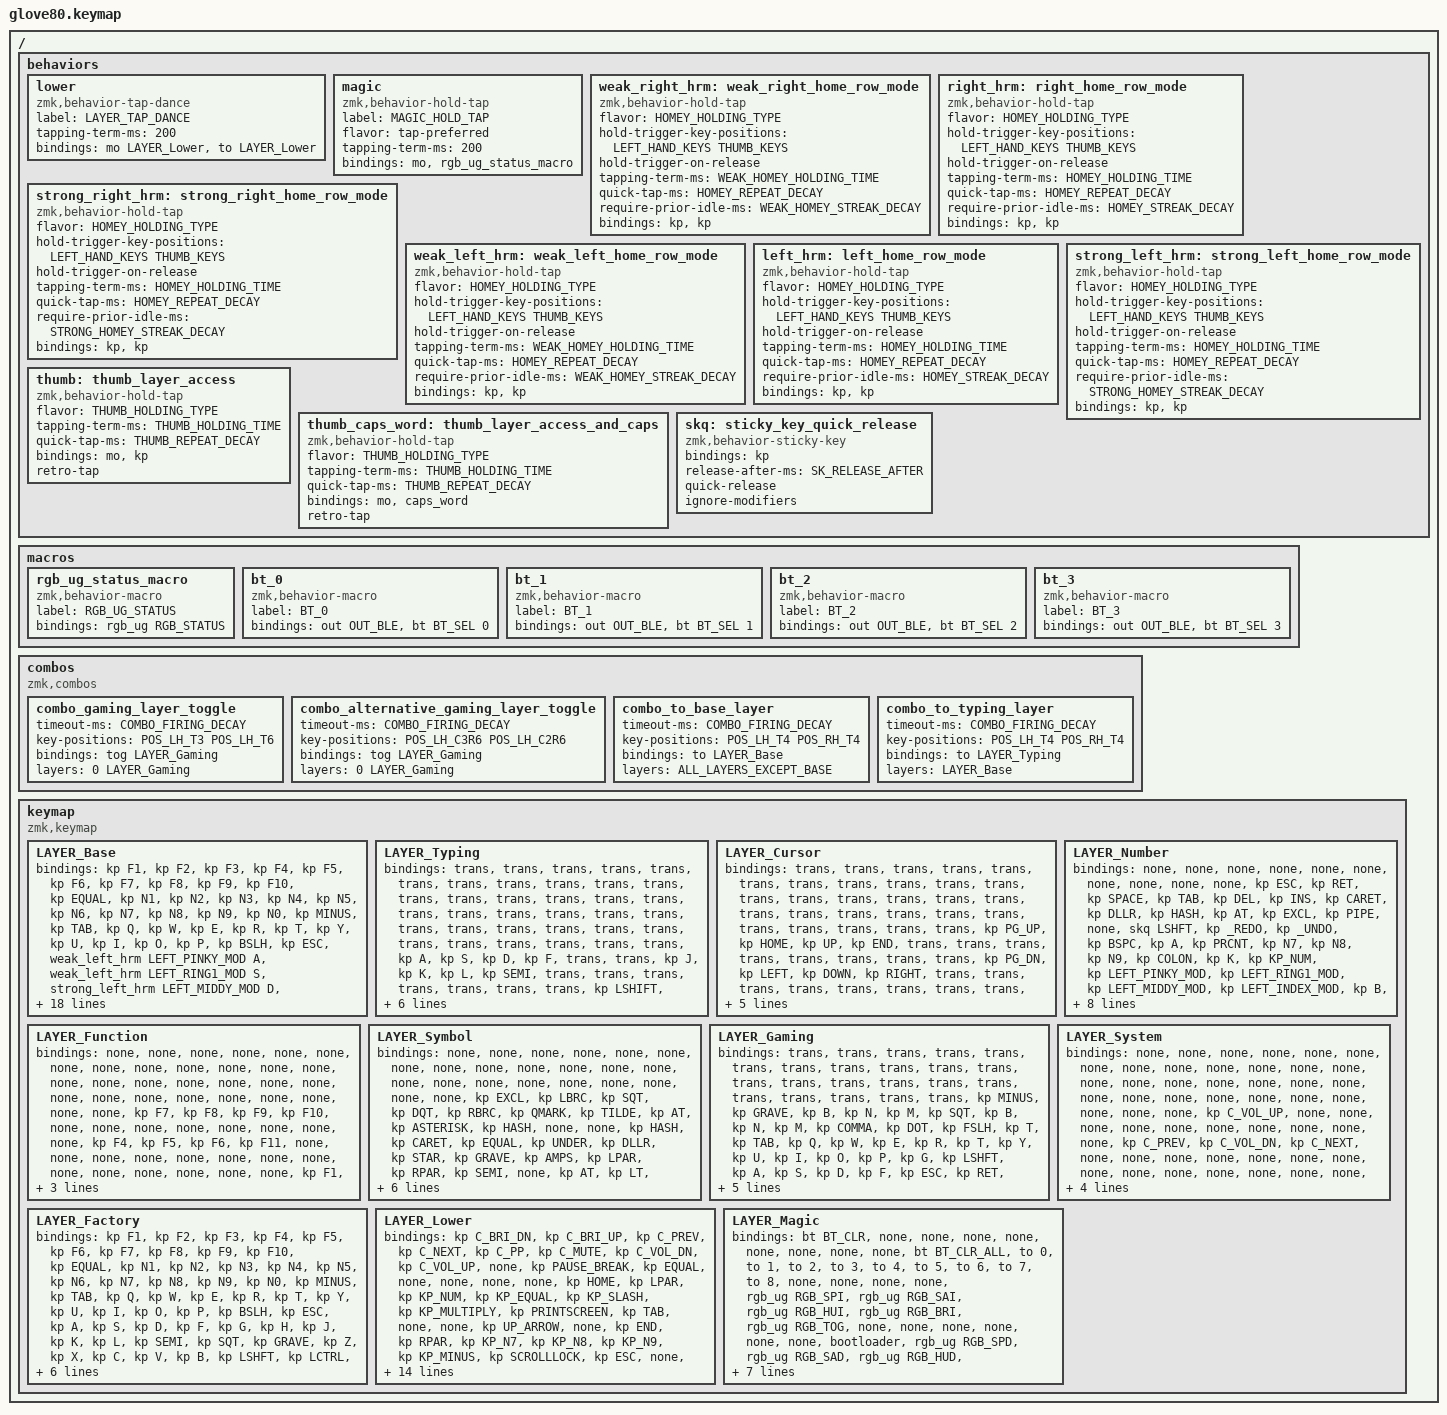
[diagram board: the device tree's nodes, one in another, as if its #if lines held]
// # vim:foldmethod=marker:foldmarker=#pragma\ region,#pragma\ endregion

/*
 * Copyright (c) 2020 The ZMK Contributors
 * Copyright (c) 2023 Innaworks Development Limited, trading as MoErgo
 *
 * SPDX-License-Identifier: MIT
 */


/* THIS FILE WAS GENERATED BY GLOVE80 LAYOUT EDITOR
 *
 * This file was generated automatically. You may or may not want to
 * edit it directly.
 */

#include <behaviors.dtsi>
/* Include all behaviour includes needed */
#include <dt-bindings/zmk/outputs.h>
#include <dt-bindings/zmk/keys.h>
#include <dt-bindings/zmk/bt.h>
#include <dt-bindings/zmk/rgb.h>
#include <dt-bindings/zmk/mouse.h>

#pragma region Layers definitions
/* Automatically generated layer name #define */
#define LAYER_Base 0
#define LAYER_Typing 1
#define LAYER_Cursor 2
#define LAYER_Number 3
#define LAYER_Function 4
#define LAYER_Symbol 5
#define LAYER_Gaming 6
#define LAYER_System 7
#define LAYER_Factory 8
#define LAYER_Lower 9
#define LAYER_Magic 10
#define ALL_LAYERS LAYER_Base LAYER_Typing LAYER_Cursor LAYER_Number LAYER_Function LAYER_Symbol LAYER_Gaming LAYER_System
#define ALL_LAYERS_EXCEPT_BASE LAYER_Typing LAYER_Cursor LAYER_Number LAYER_Function LAYER_Symbol LAYER_Gaming LAYER_System
#define ALL_LAYERS_WITH_DEFAULTS LAYER_Base LAYER_Typing LAYER_Cursor LAYER_Number LAYER_Function LAYER_Symbol LAYER_Gaming LAYER_System LAYER_Factory LAYER_Lower LAYER_Magic
#pragma endregion Layers definitions

// Info from: https://github.com/sunaku/glove80-keymaps/blob/main/keymap.zmk
// UNICODE_TARGET_OS defines which operating system you're targeting
// for the UNICODE() preprocessor macro to be used on, since each OS
// has different shortcuts for typing Unicode characters as hexcodes.
//
// NOTE: You may need to enable Unicode hexadecimal input in your OS:
// - (macOS) https://sevenseacat.net/posts/2018/unicode-in-qmk-on-osx/
// - (Linux) https://help.ubuntu.com/stable/ubuntu-help/tips-specialchars.html.en#ctrlshiftu
// - (Windows) https://github.com/samhocevar/wincompose
//
// Specifically, Windows users should be running the WinCompose tool,
// which lets you type Unicode characters via hexadecimal codepoints.
//

//
// UNICODE_SEQ_LINUX() specifies how Unicode hexadecimal codepoint
// keystrokes are transformed into Unicode characters under Linux.
//
#ifndef UNICODE_SEQ_LINUX
#define UNICODE_SEQ_LINUX(keystrokes) \
    <&macro_tap &kp LC(LS(U)) keystrokes &kp ENTER>
#endif

//
// UNICODE_SEQ_MACOS() specifies how Unicode hexadecimal codepoint
// keystrokes are transformed into Unicode characters under macOS.
//
#ifndef UNICODE_SEQ_MACOS
#define UNICODE_SEQ_MACOS(keystrokes) \
    <&macro_press &kp LALT> ,\
    <&macro_tap keystrokes> ,\
    <&macro_release &kp LALT>
#endif

//
// UNICODE_SEQ_WINDOWS() specifies how Unicode hexadecimal codepoint
// keystrokes are transformed into Unicode characters under Windows.
//
// If you've configured WinCompose to use a different trigger hotkey,
// such as F13 instead of the default RA(U) shortcut, simply override
// this definition to adapt all UNICODE() function calls accordingly.
//
#ifndef UNICODE_SEQ_WINDOWS
#define UNICODE_SEQ_WINDOWS(keystrokes) \
    <&macro_tap &kp RALT &kp U keystrokes &kp ENTER>
    #endif

#if OPERATING_SYSTEM == 'W'
    #define U_SEQ UNICODE_SEQ_WINDOWS
#elif OPERATING_SYSTEM == 'M'
    #define U_SEQ UNICODE_SEQ_MACOS
#elif OPERATING_SYSTEM == 'L'
    #define U_SEQ UNICODE_SEQ_LINUX
#endif

#pragma region Glove80 standard behaviours and macros
/* Glove80 system behavior & macros */
/ {
    behaviors {
        // For the "layer" key, it'd nice to be able to use it as either a shift or a toggle.
        // Configure it as a tap dance, so the first tap (or hold) is a &mo and the second tap is a &to
        lower: lower {
            compatible = "zmk,behavior-tap-dance";
            label = "LAYER_TAP_DANCE";
            #binding-cells = <0>;
            tapping-term-ms = <200>;
            bindings = <&mo LAYER_Lower>, <&to LAYER_Lower>;
        };
    };
};

/ {
    macros {
        rgb_ug_status_macro: rgb_ug_status_macro {
            label = "RGB_UG_STATUS";
            compatible = "zmk,behavior-macro";
            #binding-cells = <0>;
            bindings
                = <&rgb_ug RGB_STATUS>;
        };
    };
};

#pragma region bluetooth behaviours
/ {
    macros {
        bt_0: bt_0 {
            label = "BT_0";
            compatible = "zmk,behavior-macro";
            #binding-cells = <0>;
            bindings
                = <&out OUT_BLE>,
                  <&bt BT_SEL 0>;
        };
        bt_1: bt_1 {
            label = "BT_1";
            compatible = "zmk,behavior-macro";
            #binding-cells = <0>;
            bindings
                = <&out OUT_BLE>,
                  <&bt BT_SEL 1>;
        };
        bt_2: bt_2 {
            label = "BT_2";
            compatible = "zmk,behavior-macro";
            #binding-cells = <0>;
            bindings
                = <&out OUT_BLE>,
                  <&bt BT_SEL 2>;
        };
        bt_3: bt_3 {
            label = "BT_3";
            compatible = "zmk,behavior-macro";
            #binding-cells = <0>;
            bindings
                = <&out OUT_BLE>,
                  <&bt BT_SEL 3>;
        };
    };
};
#pragma endregion bluetooth behaviours

/ {
    behaviors {
        magic: magic {
            compatible = "zmk,behavior-hold-tap";
            label = "MAGIC_HOLD_TAP";
            #binding-cells = <2>;
            flavor = "tap-preferred";
            tapping-term-ms = <200>;
            bindings = <&mo>, <&rgb_ug_status_macro>;
        };
    };
};
#pragma endregion Glove80 standard behaviours and macros

#pragma region key position definitions
/* #define for key positions */
#define POS_LH_T1 52
#define POS_LH_T2 53
#define POS_LH_T3 54
#define POS_LH_T4 69
#define POS_LH_T5 70
#define POS_LH_T6 71
#define POS_LH_C1R2 15
#define POS_LH_C1R3 27
#define POS_LH_C1R4 39
#define POS_LH_C1R5 51
#define POS_LH_C2R1 4
#define POS_LH_C2R2 14
#define POS_LH_C2R3 26
#define POS_LH_C2R4 38
#define POS_LH_C2R5 50
#define POS_LH_C2R6 68
#define POS_LH_C3R1 3
#define POS_LH_C3R2 13
#define POS_LH_C3R3 25
#define POS_LH_C3R4 37
#define POS_LH_C3R5 49
#define POS_LH_C3R6 67
#define POS_LH_C4R1 2
#define POS_LH_C4R2 12
#define POS_LH_C4R3 24
#define POS_LH_C4R4 36
#define POS_LH_C4R5 48
#define POS_LH_C4R6 66
#define POS_LH_C5R1 1
#define POS_LH_C5R2 11
#define POS_LH_C5R3 23
#define POS_LH_C5R4 35
#define POS_LH_C5R5 47
#define POS_LH_C5R6 65
#define POS_LH_C6R1 0
#define POS_LH_C6R2 10
#define POS_LH_C6R3 22
#define POS_LH_C6R4 34
#define POS_LH_C6R5 46
#define POS_LH_C6R6 64
#define POS_RH_T1 57
#define POS_RH_T2 56
#define POS_RH_T3 55
#define POS_RH_T4 74
#define POS_RH_T5 73
#define POS_RH_T6 72
#define POS_RH_C1R2 16
#define POS_RH_C1R3 28
#define POS_RH_C1R4 40
#define POS_RH_C1R5 58
#define POS_RH_C2R1 5
#define POS_RH_C2R2 17
#define POS_RH_C2R3 29
#define POS_RH_C2R4 41
#define POS_RH_C2R5 59
#define POS_RH_C2R6 75
#define POS_RH_C3R1 6
#define POS_RH_C3R2 18
#define POS_RH_C3R3 30
#define POS_RH_C3R4 42
#define POS_RH_C3R5 60
#define POS_RH_C3R6 76
#define POS_RH_C4R1 7
#define POS_RH_C4R2 19
#define POS_RH_C4R3 31
#define POS_RH_C4R4 43
#define POS_RH_C4R5 61
#define POS_RH_C4R6 77
#define POS_RH_C5R1 8
#define POS_RH_C5R2 20
#define POS_RH_C5R3 32
#define POS_RH_C5R4 44
#define POS_RH_C5R5 62
#define POS_RH_C5R6 78
#define POS_RH_C6R1 9
#define POS_RH_C6R2 21
#define POS_RH_C6R3 33
#define POS_RH_C6R4 45
#define POS_RH_C6R5 63
#define POS_RH_C6R6 79
#pragma endregion key position definitions

/* Custom Defined Behaviors */
/ {
#define DIFFICULTY_LEVEL 4 // 0:custom, 1:easy -> 5:hard (see below)
#define OPERATING_SYSTEM 'M' // mac
#define PINKY_FINGER_MOD LCTL
#define RING1_FINGER_MOD LALT
#define MIDDY_FINGER_MOD LSHFT
#define INDEX_FINGER_MOD LGUI
// Default for lvl 4 is (((6 - 4) *  50) + 100) = 200
// Default for lvl 5 is (((6 - 5) *  50) + 100) = 150
#define HOMEY_STREAK_DECAY 150
#define WEAK_HOMEY_STREAK_DECAY (HOMEY_STREAK_DECAY+15)

#if OPERATING_SYSTEM == 'M'
    #define _LANG_CHANGE LC(SPACE)
#else
    #define _LANG_CHANGE LG(SPACE)
#endif

////////////////////////////////////////////////////////////////////////////
//
// Sunaku's Keymap v36 -- "Glorious Engrammer"
// - https://github.com/sunaku/glove80-keymaps
//
//////////////////////////////////////////////////////////////////////////////

//
// DIFFICULTY_LEVEL specifies your level of expertise with this keymap.
// It's meant to help newcomers gradually work their way up to mastery.
// You can disable this setting by omitting it or assigning a `0` zero.
//
// #define DIFFICULTY_LEVEL 0 // custom (see defaults below)
// #define DIFFICULTY_LEVEL 1 // novice (500ms)
// #define DIFFICULTY_LEVEL 2 // slower (400ms)
// #define DIFFICULTY_LEVEL 3 // normal (300ms)
// #define DIFFICULTY_LEVEL 4 // faster (200ms)
// #define DIFFICULTY_LEVEL 5 // expert (100ms)
//
#if defined(DIFFICULTY_LEVEL) && DIFFICULTY_LEVEL > 0
#ifndef DIFFICULTY_LEVEL_HOLDING_TIME
#define DIFFICULTY_LEVEL_HOLDING_TIME  ((6 - DIFFICULTY_LEVEL) * 100)
#endif
#ifndef DIFFICULTY_LEVEL_STREAK_DECAY
#define DIFFICULTY_LEVEL_STREAK_DECAY (((6 - DIFFICULTY_LEVEL) *  50) + 100)
#endif
#ifndef HOMEY_HOLDING_TIME
#define HOMEY_HOLDING_TIME DIFFICULTY_LEVEL_HOLDING_TIME
#endif
#ifndef HOMEY_STREAK_DECAY
#define HOMEY_STREAK_DECAY DIFFICULTY_LEVEL_STREAK_DECAY
#endif
#ifndef INDEX_HOLDING_TIME
#define INDEX_HOLDING_TIME DIFFICULTY_LEVEL_HOLDING_TIME
#endif
#ifndef INDEX_STREAK_DECAY
#define INDEX_STREAK_DECAY DIFFICULTY_LEVEL_STREAK_DECAY
#endif
#endif

#ifndef WEAK_HOMEY_HOLDING_TIME
#define WEAK_HOMEY_HOLDING_TIME (HOMEY_HOLDING_TIME+50)
#endif
#ifndef WEAK_HOMEY_STREAK_DECAY
#define WEAK_HOMEY_STREAK_DECAY (HOMEY_STREAK_DECAY+50)
#endif
#ifndef STRONG_HOMEY_STREAK_DECAY
#define STRONG_HOMEY_STREAK_DECAY (HOMEY_STREAK_DECAY-50)
#endif

// Defines how long sticky key shoud be waiting for the next key
#define SK_RELEASE_AFTER 1000

//
// OPERATING_SYSTEM defines which operating system you intend to use
// with this keymap, because shortcuts vary across operating systems.
//
// - https://zmk.dev/docs/codes
// - https://en.wikipedia.org/wiki/Table_of_keyboard_shortcuts
//
#ifndef OPERATING_SYSTEM
//define OPERATING_SYSTEM 'L' // linux
//#define OPERATING_SYSTEM 'M' // macos
#define OPERATING_SYSTEM 'W' // windows
#endif

#pragma region shortcuts definitions
#if OPERATING_SYSTEM == 'M'
    #define _C      LG
    #define _G_TAB  LALT
    #define _REDO   _C(LS(Z))
    #define _POWER  K_POWER
    #define _W      LA
    #define _HOME   _C(LEFT)
    #define _END    _C(RIGHT)
#else
    #define _C      LC
    #define _G_TAB  LGUI
    #define _REDO   _C(Y)
    #define _POWER  C_POWER
    #define _W      _C
    #define _HOME   HOME
    #define _END    END
#endif
#define _SLEEP      C_SLEEP
#if OPERATING_SYSTEM == 'W'
    #define _LOCK   LG(L)
#elif OPERATING_SYSTEM == 'M'
    #define _LOCK   _C(LC(Q))
#elif OPERATING_SYSTEM == 'L'
    #define _LOCK   K_LOCK
#endif
#define _UNDO       _C(Z)
#define _CUT        _C(X)
#define _COPY       _C(C)
#define _PASTE      _C(V)
#define _FIND       _C(F)
#define _FIND_NEXT  _C(G)
#define _FIND_PREV  _C(LS(G))
#pragma endregion shortcuts definitions

combos {
    compatible = "zmk,combos";

    //
    // COMBO_FIRING_DECAY defines how much time you have left (milliseconds)
    // after pressing the first key in a ZMK combo to finish the whole chord.
    //
    #ifndef COMBO_FIRING_DECAY
    #define COMBO_FIRING_DECAY 50
    #endif
    #ifdef LAYER_Gaming
    combo_gaming_layer_toggle {
        timeout-ms = <COMBO_FIRING_DECAY>;
        key-positions = <POS_LH_T3 POS_LH_T6>;
        bindings = <&tog LAYER_Gaming>;
        layers = <0 LAYER_Gaming>;
    };
    combo_alternative_gaming_layer_toggle {
        timeout-ms = <COMBO_FIRING_DECAY>;
        key-positions = <POS_LH_C3R6 POS_LH_C2R6>;
        bindings = <&tog LAYER_Gaming>;
        layers = <0 LAYER_Gaming>;
    };
    #endif

    combo_to_base_layer {
        timeout-ms = <COMBO_FIRING_DECAY>;
        key-positions = <POS_LH_T4 POS_RH_T4>;
        bindings = <&to LAYER_Base>;
        layers = <ALL_LAYERS_EXCEPT_BASE>;
    };

    combo_to_typing_layer {
        timeout-ms = <COMBO_FIRING_DECAY>;
        key-positions = <POS_LH_T4 POS_RH_T4>;
        bindings = <&to LAYER_Typing>;
        layers = <LAYER_Base>;
    };

};

behaviors {

#pragma region homerow modes fingers configuration
    //////////////////////////////////////////////////////////////////////////
    //
    // Miryoku layers and home row mods (ported from my QMK endgame)
    // - https://sunaku.github.io/home-row-mods.html#porting-to-zmk
    // - https://github.com/urob/zmk-config#timeless-homerow-mods
    //
    //////////////////////////////////////////////////////////////////////////

    //
    // The *_FINGER_MOD specify which modifiers are used by home row mod keys.
    // Here, we use Miryoku's "GACS" (Win, Alt, Ctrl, Shift) order by default,
    // unless OPERATING_SYSTEM is macOS, in which case Win & Ctrl are swapped.
    //
    #ifndef PINKY_FINGER_MOD
      #if OPERATING_SYSTEM == 'M'
        #define PINKY_FINGER_MOD LCTL
      #else
        #define PINKY_FINGER_MOD LGUI
      #endif
    #endif
    #ifndef RING1_FINGER_MOD
    #define RING1_FINGER_MOD LALT
    #endif
    #ifndef RING2_FINGER_MOD
    #define RING2_FINGER_MOD RALT
    #endif
    #ifndef MIDDY_FINGER_MOD
      #if OPERATING_SYSTEM == 'M'
        #define MIDDY_FINGER_MOD LGUI
      #else
        #define MIDDY_FINGER_MOD LCTL
      #endif
    #endif
    #ifndef INDEX_FINGER_MOD
    #define INDEX_FINGER_MOD LSFT
    #endif
    //
    // The following settings let you configure mods individually, per finger:
    //
    #ifndef LEFT_PINKY_MOD
    #define LEFT_PINKY_MOD  PINKY_FINGER_MOD
    #endif
    #ifndef RIGHT_PINKY_MOD
    #define RIGHT_PINKY_MOD PINKY_FINGER_MOD
    #endif
    #ifndef LEFT_RING1_MOD
    #define LEFT_RING1_MOD  RING1_FINGER_MOD
    #endif
    #ifndef RIGHT_RING1_MOD
    #define RIGHT_RING1_MOD RING1_FINGER_MOD
    #endif
    #ifndef LEFT_RING2_MOD
    #define LEFT_RING2_MOD  RING2_FINGER_MOD
    #endif
    #ifndef RIGHT_RING2_MOD
    #define RIGHT_RING2_MOD RING2_FINGER_MOD
    #endif
    #ifndef LEFT_MIDDY_MOD
    #define LEFT_MIDDY_MOD  MIDDY_FINGER_MOD
    #endif
    #ifndef RIGHT_MIDDY_MOD
    #define RIGHT_MIDDY_MOD MIDDY_FINGER_MOD
    #endif
    #ifndef LEFT_INDEX_MOD
    #define LEFT_INDEX_MOD  INDEX_FINGER_MOD
    #endif
    #ifndef RIGHT_INDEX_MOD
    #define RIGHT_INDEX_MOD INDEX_FINGER_MOD
    #endif
#pragma endregion homerow modes fingers configuration

#pragma region homerow modes timing configuration
    //
    // HOMEY_HOLDING_TYPE defines the flavor of ZMK hold-tap behavior to use
    // for the pinky, ring, and middle fingers (which are assigned to Super,
    // Alt, and Ctrl respectively in the Miryoku system) on home row keys.
    //
    #ifndef HOMEY_HOLDING_TYPE
    #define HOMEY_HOLDING_TYPE "tap-preferred"
    #endif

    //
    // HOMEY_HOLDING_TIME defines how long you need to hold (milliseconds)
    // home row mod keys in order to send their modifiers to the computer
    // (i.e. "register" them) for mod-click mouse usage (e.g. Ctrl-Click).
    //
    #ifndef HOMEY_HOLDING_TIME
    #define HOMEY_HOLDING_TIME 240 // TAPPING_TERM + ALLOW_CROSSOVER_AFTER
    #endif

    //
    // HOMEY_STREAK_DECAY defines how long you need to wait (milliseconds)
    // after typing before you can use home row mods again.  It prevents
    // unintended activation of home row mods when you're actively typing.
    //
    #ifndef HOMEY_STREAK_DECAY
    #define HOMEY_STREAK_DECAY 160
    #endif

    //
    // HOMEY_REPEAT_DECAY defines how much time you have left (milliseconds)
    // after tapping a key to hold it again in order to make it auto-repeat.
    //
    #ifndef HOMEY_REPEAT_DECAY
    #define HOMEY_REPEAT_DECAY 300 // "tap then hold" for key auto-repeat
    #endif

    //
    // CHORD_HOLDING_TYPE defines the flavor of ZMK hold-tap behavior to use
    // for chorded home row mods (secondary keypresses in multi-mod chords).
    //
    #ifndef CHORD_HOLDING_TYPE
    #define CHORD_HOLDING_TYPE HOMEY_HOLDING_TYPE
    #endif

    //
    // CHORD_HOLDING_TIME defines how long you need to hold (milliseconds)
    // home row mod keys in order to send their modifiers to the computer
    // (i.e. "register" them) for mod-click mouse usage (e.g. Ctrl-Click).
    // This is specifically for secondary keypresses in multi-mod chords.
    //
    #ifndef CHORD_HOLDING_TIME
    #define CHORD_HOLDING_TIME 150
    #endif

    //
    // CHORD_STREAK_DECAY defines how long you need to wait (milliseconds)
    // after typing before you can use home row mods again.  It prevents
    // unintended activation of home row mods when you're actively typing
    // This is specifically for secondary keypresses in multi-mod chords.
    //
    #ifndef CHORD_STREAK_DECAY
    #define CHORD_STREAK_DECAY HOMEY_STREAK_DECAY
    #endif

    //
    // CHORD_REPEAT_DECAY defines how much time you have left (milliseconds)
    // after tapping a key to hold it again in order to make it auto-repeat.
    // This is specifically for secondary keypresses in multi-mod chords.
    //
    #ifndef CHORD_REPEAT_DECAY
    #define CHORD_REPEAT_DECAY HOMEY_REPEAT_DECAY
    #endif

    //
    // THUMB_HOLDING_TYPE defines the flavor of ZMK hold-tap behavior to use
    // for the thumbs (which are assigned to 6 layers in the Miryoku system).
    //
    // NOTE: The "balanced" flavor of ZMK hold-tap provides instant modifier
    // activation for the symbol layer (if the tapped symbol key is released
    // while the thumb layer key is still held down) for quicker programming.
    //
    #ifndef THUMB_HOLDING_TYPE
    #define THUMB_HOLDING_TYPE "balanced"
    #endif

    //
    // THUMB_HOLDING_TIME defines how long you need to hold (milliseconds)
    // a thumb key to activate a layer.  Shorter holds are treated as taps.
    //
    #ifndef THUMB_HOLDING_TIME
    #define THUMB_HOLDING_TIME 200
    #endif

    //
    // THUMB_REPEAT_DECAY defines how much time you have left (milliseconds)
    // after tapping a key to hold it again in order to make it auto-repeat.
    //
    #ifndef THUMB_REPEAT_DECAY
    #define THUMB_REPEAT_DECAY 300 // "tap then hold" for key auto-repeat
    #endif

#pragma endregion homerow modes timing configuration

#pragma region keys setup
    //
    // Glove80 key positions index for positional hold-tap
    // - https://discord.com/channels/877392805654306816/937645688244826154/1066713913351221248
    // - https://media.discordapp.net/attachments/937645688244826154/1066713913133121556/image.png
    //
    // |------------------------|------------------------|
    // | LEFT_HAND_KEYS         |        RIGHT_HAND_KEYS |
    // |                        |                        |
    // |  0  1  2  3  4         |          5  6  7  8  9 |
    // | 10 11 12 13 14 15      |      16 17 18 19 20 21 |
    // | 22 23 24 25 26 27      |      28 29 30 31 32 33 |
    // | 34 35 36 37 38 39      |      40 41 42 43 44 45 |
    // | 46 47 48 49 50 51      |      58 59 60 61 62 63 |
    // | 64 65 66 67 68         |         75 76 77 78 79 |
    // |                69 52   |   57 74                |
    // |                 70 53  |  56 73                 |
    // |                  71 54 | 55 72                  |
    // |------------------------|------------------------|
    //
    #define LEFT_HAND_KEYS      \
          0  1  2  3  4         \
         10 11 12 13 14 15      \
         22 23 24 25 26 27      \
         34 35 36 37 38 39      \
         46 47 48 49 50 51      \
         64 65 66 67 68
    #define RIGHT_HAND_KEYS     \
                                           5  6  7  8  9 \
                                       16 17 18 19 20 21 \
                                       28 29 30 31 32 33 \
                                       40 41 42 43 44 45 \
                                       58 59 60 61 62 63 \
                                          75 76 77 78 79
    #define THUMB_KEYS          \
                        69 52       57 74                \
                         70 53     56 73                 \
                          71 54   55 72
#pragma endregion keys setup

    weak_right_hrm: weak_right_home_row_mode {
        compatible = "zmk,behavior-hold-tap";
        flavor = HOMEY_HOLDING_TYPE;
        hold-trigger-key-positions = <LEFT_HAND_KEYS THUMB_KEYS>;
        hold-trigger-on-release; // wait for other home row mods
        tapping-term-ms = <WEAK_HOMEY_HOLDING_TIME>;
        quick-tap-ms = <HOMEY_REPEAT_DECAY>;
        require-prior-idle-ms = <WEAK_HOMEY_STREAK_DECAY>;
        #binding-cells = <2>;
        bindings = <&kp>, <&kp>;
    };

    right_hrm: right_home_row_mode {
        compatible = "zmk,behavior-hold-tap";
        flavor = HOMEY_HOLDING_TYPE;
        hold-trigger-key-positions = <LEFT_HAND_KEYS THUMB_KEYS>;
        hold-trigger-on-release; // wait for other home row mods
        tapping-term-ms = <HOMEY_HOLDING_TIME>;
        quick-tap-ms = <HOMEY_REPEAT_DECAY>;
        require-prior-idle-ms = <HOMEY_STREAK_DECAY>;
        #binding-cells = <2>;
        bindings = <&kp>, <&kp>;
    };

    strong_right_hrm: strong_right_home_row_mode {
        compatible = "zmk,behavior-hold-tap";
        flavor = HOMEY_HOLDING_TYPE;
        hold-trigger-key-positions = <LEFT_HAND_KEYS THUMB_KEYS>;
        hold-trigger-on-release; // wait for other home row mods
        tapping-term-ms = <HOMEY_HOLDING_TIME>;
        quick-tap-ms = <HOMEY_REPEAT_DECAY>;
        require-prior-idle-ms = <STRONG_HOMEY_STREAK_DECAY>;
        #binding-cells = <2>;
        bindings = <&kp>, <&kp>;
    };


    weak_left_hrm: weak_left_home_row_mode {
        compatible = "zmk,behavior-hold-tap";
        flavor = HOMEY_HOLDING_TYPE;
        hold-trigger-key-positions = <LEFT_HAND_KEYS THUMB_KEYS>;
        hold-trigger-on-release; // wait for other home row mods
        tapping-term-ms = <WEAK_HOMEY_HOLDING_TIME>;
        quick-tap-ms = <HOMEY_REPEAT_DECAY>;
        require-prior-idle-ms = <WEAK_HOMEY_STREAK_DECAY>;
        #binding-cells = <2>;
        bindings = <&kp>, <&kp>;
    };

    left_hrm: left_home_row_mode {
        compatible = "zmk,behavior-hold-tap";
        flavor = HOMEY_HOLDING_TYPE;
        hold-trigger-key-positions = <LEFT_HAND_KEYS THUMB_KEYS>;
        hold-trigger-on-release; // wait for other home row mods
        tapping-term-ms = <HOMEY_HOLDING_TIME>;
        quick-tap-ms = <HOMEY_REPEAT_DECAY>;
        require-prior-idle-ms = <HOMEY_STREAK_DECAY>;
        #binding-cells = <2>;
        bindings = <&kp>, <&kp>;
    };

    strong_left_hrm: strong_left_home_row_mode {
        compatible = "zmk,behavior-hold-tap";
        flavor = HOMEY_HOLDING_TYPE;
        hold-trigger-key-positions = <LEFT_HAND_KEYS THUMB_KEYS>;
        hold-trigger-on-release; // wait for other home row mods
        tapping-term-ms = <HOMEY_HOLDING_TIME>;
        quick-tap-ms = <HOMEY_REPEAT_DECAY>;
        require-prior-idle-ms = <STRONG_HOMEY_STREAK_DECAY>;
        #binding-cells = <2>;
        bindings = <&kp>, <&kp>;
    };

    //
    // Thumb cluster hold-tap keys for Miryoku layers
    //
    thumb: thumb_layer_access {
        compatible = "zmk,behavior-hold-tap";
        flavor = THUMB_HOLDING_TYPE;
        tapping-term-ms = <THUMB_HOLDING_TIME>;
        quick-tap-ms = <THUMB_REPEAT_DECAY>; // enable repeat
        #binding-cells = <2>;
        bindings = <&mo>, <&kp>;
        retro-tap; // tap on standalone hold
    };

    thumb_caps_word: thumb_layer_access_and_caps {
        compatible = "zmk,behavior-hold-tap";
        flavor = THUMB_HOLDING_TYPE;
        tapping-term-ms = <THUMB_HOLDING_TIME>;
        quick-tap-ms = <THUMB_REPEAT_DECAY>; // enable repeat
        #binding-cells = <2>;
        bindings = <&mo>, <&caps_word>;
        retro-tap; // tap on standalone hold
    };

    skq: sticky_key_quick_release {
        compatible = "zmk,behavior-sticky-key";
        #binding-cells = <1>;
        bindings = <&kp>;
        release-after-ms = <SK_RELEASE_AFTER>;
        quick-release;
        ignore-modifiers;
      };
};

};

/ {
    keymap {
        compatible = "zmk,keymap";

        LAYER_Base {
            bindings = <
               &kp F1    &kp F2   &kp F3    &kp F4     &kp F5                                                                                  &kp F6     &kp F7    &kp F8    &kp F9    &kp F10
            &kp EQUAL    &kp N1   &kp N2    &kp N3     &kp N4  &kp N5                                                                  &kp N6  &kp N7     &kp N8    &kp N9    &kp N0  &kp MINUS
              &kp TAB     &kp Q    &kp W     &kp E      &kp R   &kp T                                                                   &kp Y   &kp U      &kp I     &kp O     &kp P   &kp BSLH
              &kp ESC     &weak_left_hrm LEFT_PINKY_MOD A  &weak_left_hrm LEFT_RING1_MOD S  &strong_left_hrm LEFT_MIDDY_MOD D  &left_hrm LEFT_INDEX_MOD F   &kp G                                                                   &kp H   &right_hrm RIGHT_INDEX_MOD J  &strong_right_hrm RIGHT_MIDDY_MOD K  &weak_right_hrm RIGHT_RING1_MOD L  &weak_right_hrm RIGHT_PINKY_MOD SEMI   &kp SQT
            &kp GRAVE     &kp Z    &kp X     &kp C      &kp V   &kp B  &thumb LAYER_Function ESC  &thumb_caps_word LAYER_System 0   &lower  &kp LGUI  &caps_word &kp TAB   &kp N   &kp M  &kp COMMA   &kp DOT  &kp FSLH  &kp _LANG_CHANGE
 &magic LAYER_Magic 0  &kp _LANG_CHANGE  &kp END  &kp LEFT  &kp RIGHT           &thumb LAYER_Cursor BACKSPACE    &thumb LAYER_Number DELETE  &thumb LAYER_Lower LALT  &thumb LAYER_Lower RALT    &kp RET  &thumb LAYER_Symbol SPACE          &kp UP   &kp DOWN  &kp LBKT  &kp RBKT  &kp PG_DN
            >;
        };

        LAYER_Typing {
            bindings = <
 &trans              &trans              &trans              &trans              &trans                                                                                                                                                &trans               &trans               &trans               &trans  &trans
 &trans              &trans              &trans              &trans              &trans         &trans                                                                                                            &trans               &trans               &trans               &trans               &trans  &trans
 &trans              &trans              &trans              &trans              &trans         &trans                                                                                                            &trans               &trans               &trans               &trans               &trans  &trans
 &trans              &kp A               &kp S               &kp D               &kp F          &trans                                                                                                            &trans               &kp J                &kp K                &kp L                &kp SEMI &trans
 &trans              &trans              &trans              &trans              &trans         &trans  &kp LSHIFT         &trans             &trans             &trans         &trans        &kp RSHIFT          &trans               &trans               &trans               &trans               &trans  &trans
 &trans              &trans              &trans              &trans              &trans                 &kp BACKSPACE      &kp DELETE         &trans             &trans         &kp ENTER     &kp SPACE                                &trans               &trans               &trans               &trans  &trans
            >;
        };

        LAYER_Cursor {
            bindings = <
 &trans              &trans              &trans              &trans              &trans                                                                                                                                                &trans               &trans               &trans               &trans  &trans
 &trans              &trans              &trans              &trans              &trans         &trans                                                                                                            &trans               &trans               &trans               &trans               &trans  &trans
 &trans              &trans              &trans              &trans              &trans         &trans                                                                                                            &kp PG_UP            &kp HOME             &kp UP               &kp END              &trans  &trans
 &trans              &trans              &trans              &trans              &trans         &trans                                                                                                            &kp PG_DN            &kp LEFT             &kp DOWN             &kp RIGHT            &trans  &trans
 &trans              &trans              &trans              &trans              &trans         &trans  &trans         &trans             &trans             &trans         &trans  &trans          &trans               &trans               &trans               &trans               &trans  &trans
 &trans              &trans              &trans              &trans              &trans                 &trans         &trans             &trans             &trans         &trans  &trans                               &trans               &trans               &trans               &trans  &trans
            >;
        };

        LAYER_Number {
            bindings = <
      &none               &none               &none               &none               &none                                                                                                                &none       &none       &none          &none      &none
    &kp ESC             &kp RET           &kp SPACE             &kp TAB             &kp DEL  &kp INS                                                                                       &kp CARET    &kp DLLR    &kp HASH      &kp AT       &kp EXCL   &kp PIPE
      &none           &skq LSHFT           &kp _REDO           &kp _UNDO            &kp BSPC    &kp A                                                                                       &kp PRCNT  &kp N7  &kp N8  &kp N9      &kp COLON      &kp K
 &kp KP_NUM  &kp LEFT_PINKY_MOD  &kp LEFT_RING1_MOD  &kp LEFT_MIDDY_MOD  &kp LEFT_INDEX_MOD    &kp B                                                                                    &kp PLUS  &kp N4  &kp N5  &kp N6  &kp MINUS      &kp J
      &none           &kp _C(A)               &none               &none           &kp UNDER    &kp C   &kp D   &kp E              &kp F         &kp LT       &kp GT  &kp EQUAL  &kp ASTERISK  &kp N1  &kp N2  &kp N3  &kp SLASH  &kp LS(G)
      &none               &none               &none               &none               &kp X            &none   &none  &tog LAYER_Number  &kp COMMA  &kp DOT     &kp N0                        &trans      &trans      &trans         &trans  &kp TILDE
            >;
        };

        LAYER_Function {
            bindings = <
    &none               &none               &none               &none               &none                                                                               &none         &none         &none         &none           &none
    &none               &none               &none               &none               &none    &none                                                        &none         &none         &none         &none         &none           &none
    &none               &none               &none               &none               &none    &none                                                        &none        &kp F7        &kp F8        &kp F9       &kp F10           &none
    &none               &none               &none               &none               &none    &none                                                        &none        &kp F4        &kp F5        &kp F6       &kp F11           &none
    &none               &none               &none               &none               &none    &none   &none   &none  &none          &none  &none  &none    &none        &kp F1        &kp F2        &kp F3       &kp F12           &none
    &none               &none               &none               &none               &none            &none   &none  &none          &none  &none  &none                  &none         &none         &none         &none           &none
            >;
        };

        LAYER_Symbol {
            bindings = <
     &none      &none      &none      &none     &none                                                                                                        &none                &none                &none                &none   &none
     &none      &none      &none      &none     &none      &none                                                                        &none                &none                &none                &none                &none   &none
  &kp EXCL   &kp LBRC    &kp SQT    &kp DQT  &kp RBRC  &kp QMARK                                                                    &kp TILDE               &kp AT         &kp ASTERISK             &kp HASH                &none   &none
  &kp HASH  &kp CARET  &kp EQUAL  &kp UNDER  &kp DLLR   &kp STAR                                                                    &kp GRAVE             &kp AMPS             &kp LPAR             &kp RPAR             &kp SEMI   &none
    &kp AT     &kp LT   &kp PIPE  &kp MINUS    &kp GT   &kp FSLH   &kp BSLH      &none  &none                 &none   &none   &none     &none             &kp LBKT             &kp PLUS            &kp MINUS             &kp RBKT   &none
 &kp TILDE   &kp AMPS   &kp LBKT   &kp RBKT  &kp PLUS             &kp PRCNT  &kp COLON  &none  &none   &none   &none                          &none                &none                &none                &none   &none
            >;
        };

        LAYER_Gaming {
            bindings = <
    &trans     &trans  &trans  &trans  &trans                                                                                             &trans  &trans     &trans   &trans    &trans
    &trans     &trans  &trans  &trans  &trans   &trans                                                                            &trans  &trans  &trans     &trans   &trans    &trans
 &kp MINUS  &kp GRAVE   &kp B   &kp N   &kp M  &kp SQT                                                                             &kp B   &kp N   &kp M  &kp COMMA  &kp DOT  &kp FSLH
     &kp T    &kp TAB   &kp Q   &kp W   &kp E    &kp R                                                                             &kp T   &kp Y   &kp U      &kp I    &kp O     &kp P
     &kp G  &kp LSHFT   &kp A   &kp S   &kp D    &kp F    &kp ESC   &kp RET  &kp PAUSE_BREAK           &kp BSPC  &kp DEL  &trans   &kp G   &kp H   &kp J      &kp K    &kp L  &kp SEMI
     &kp V  &kp LCTRL   &kp Z   &kp X   &kp C           &kp SPACE  &kp LALT         &kp LGUI  &tog LAYER_Gaming   &trans  &trans          &trans  &trans     &trans   &trans    &trans
            >;
        };

        LAYER_System {
            bindings = <
 &none              &none              &none              &none              &none                                                                                                                                                &none               &none               &none               &none  &none
 &none              &none              &none              &none              &none         &none                                                                                                              &none               &none               &none               &none               &none  &none
 &none              &none              &none              &none              &none         &none                                                                                                             &none                &none        &kp C_VOL_UP               &none               &none  &none
 &none              &none              &none              &none              &none         &none                                                                                                             &none           &kp C_PREV        &kp C_VOL_DN          &kp C_NEXT               &none  &none
 &none              &none              &none              &none              &none         &none  &none         &none             &none             &none         &none  &none                               &none         &kp C_BRI_DN               &none        &kp C_BRI_UP               &none  &none
 &none              &none              &none              &none              &none                 &none         &none             &none             &none         &kp C_MUTE  &kp C_PP                                          &none                &none               &none               &none  &none
            >;
        };

        LAYER_Factory {
            bindings = <
               &kp F1    &kp F2   &kp F3    &kp F4     &kp F5                                                                                  &kp F6     &kp F7    &kp F8    &kp F9    &kp F10
            &kp EQUAL    &kp N1   &kp N2    &kp N3     &kp N4  &kp N5                                                                  &kp N6  &kp N7     &kp N8    &kp N9    &kp N0  &kp MINUS
              &kp TAB     &kp Q    &kp W     &kp E      &kp R   &kp T                                                                   &kp Y   &kp U      &kp I     &kp O     &kp P   &kp BSLH
              &kp ESC     &kp A    &kp S     &kp D      &kp F   &kp G                                                                   &kp H   &kp J      &kp K     &kp L  &kp SEMI    &kp SQT
            &kp GRAVE     &kp Z    &kp X     &kp C      &kp V   &kp B  &kp LSHFT  &kp LCTRL    &lower  &kp LGUI  &kp RCTRL  &kp RSHFT   &kp N   &kp M  &kp COMMA   &kp DOT  &kp FSLH  &kp PG_UP
 &magic LAYER_Magic 0  &kp HOME  &kp END  &kp LEFT  &kp RIGHT           &kp BSPC    &kp DEL  &kp LALT  &kp RALT    &kp RET  &kp SPACE          &kp UP   &kp DOWN  &kp LBKT  &kp RBKT  &kp PG_DN
            >;
        };

        LAYER_Lower {
            bindings = <
         &kp C_BRI_DN  &kp C_BRI_UP      &kp C_PREV      &kp C_NEXT          &kp C_PP                                                                                                                                                    &kp C_MUTE  &kp C_VOL_DN  &kp C_VOL_UP            &none       &kp PAUSE_BREAK
            &kp EQUAL         &none           &none           &none             &none   &kp HOME                                                                                                                         &kp LPAR        &kp KP_NUM  &kp KP_EQUAL  &kp KP_SLASH  &kp KP_MULTIPLY       &kp PRINTSCREEN
              &kp TAB         &none           &none    &kp UP_ARROW             &none    &kp END                                                                                                                         &kp RPAR         &kp KP_N7     &kp KP_N8     &kp KP_N9     &kp KP_MINUS        &kp SCROLLLOCK
              &kp ESC         &none  &kp LEFT_ARROW  &kp DOWN_ARROW   &kp RIGHT_ARROW  &kp PG_UP                                                                                                                      &kp PERCENT         &kp KP_N4     &kp KP_N5     &kp KP_N6      &kp KP_PLUS            &kp KP_NUM
            &kp GRAVE     &kp K_APP           &none         &kp F11           &kp F12  &kp PG_DN  &tog LAYER_Function  &tog LAYER_Typing  &tog LAYER_Gaming  &tog LAYER_Gaming  &tog LAYER_Typing  &none    &kp COMMA         &kp KP_N1     &kp KP_N2     &kp KP_N3     &kp KP_ENTER              &kp LALT
 &magic LAYER_Magic 0      &kp CAPS         &kp INS         &kp F11           &none               &tog LAYER_Cursor  &tog LAYER_Number   &tog LAYER_Lower   &tog LAYER_Lower   &none  &tog LAYER_Symbol               &none     &kp KP_N0    &kp KP_DOT     &kp KP_ENTER  &magic LAYER_Magic 0
            >;
        };

        LAYER_Magic {
            bindings = <
  &bt BT_CLR            &none            &none            &none            &none                                                                                  &none   &none   &none   &none  &bt BT_CLR_ALL
       &to 0            &to 1            &to 2            &to 3            &to 4            &to 5                                                         &to 6   &to 7   &to 8   &none   &none           &none
       &none  &rgb_ug RGB_SPI  &rgb_ug RGB_SAI  &rgb_ug RGB_HUI  &rgb_ug RGB_BRI  &rgb_ug RGB_TOG                                                         &none   &none   &none   &none   &none           &none
 &bootloader  &rgb_ug RGB_SPD  &rgb_ug RGB_SAD  &rgb_ug RGB_HUD  &rgb_ug RGB_BRD  &rgb_ug RGB_EFF                                                         &none   &none   &none   &none   &none     &bootloader
  &sys_reset            &none            &none            &none            &none            &none   &bt_2   &bt_3       &tog 29   &none   &none   &none   &none   &none   &none   &none   &none      &sys_reset
       &none            &none            &none            &none            &none                    &bt_0   &bt_1  &out OUT_USB   &none   &none   &none           &none   &none   &none   &none           &none
            >;
        };

    };
};
